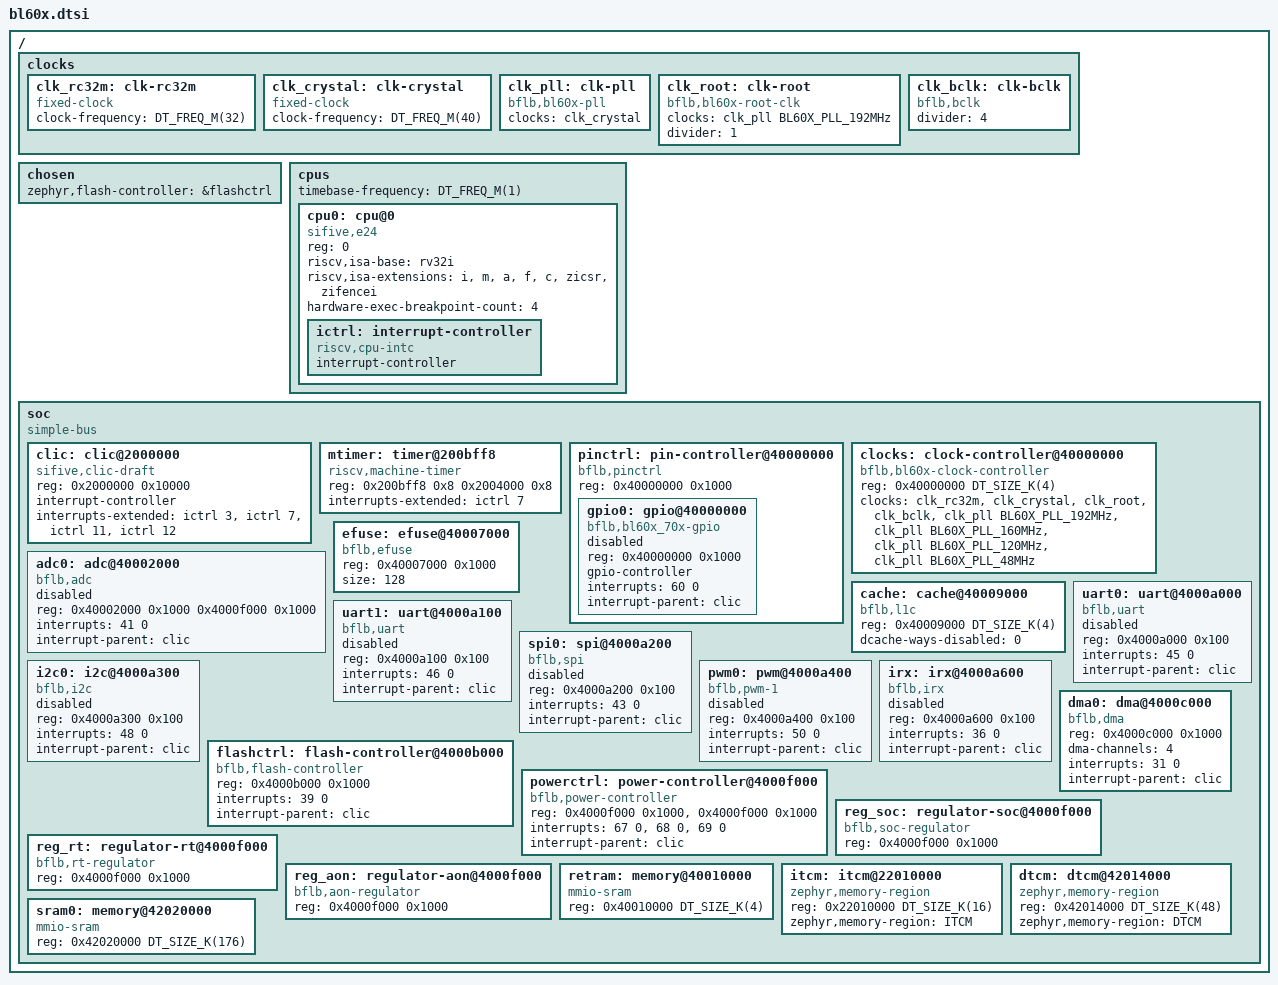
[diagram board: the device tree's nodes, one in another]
/*
 * Copyright (c) 2021-2025 ATL Electronics
 * Copyright (c) 2024-2026 MASSDRIVER EI (massdriver.space)
 *
 * SPDX-License-Identifier: Apache-2.0
 */

#include <freq.h>
#include <mem.h>
#include <zephyr/dt-bindings/pinctrl/bflb-common-pinctrl.h>
#include <zephyr/dt-bindings/pinctrl/bl60x-pinctrl.h>
#include <zephyr/dt-bindings/clock/bflb_bl60x_clock.h>
#include <zephyr/dt-bindings/gpio/gpio.h>
#include <zephyr/dt-bindings/input/input-event-codes.h>
#include <zephyr/dt-bindings/i2c/i2c.h>
#include <zephyr/dt-bindings/spi/spi.h>
#include <zephyr/dt-bindings/pwm/pwm.h>
#include <zephyr/dt-bindings/adc/adc.h>

/ {
	#address-cells = <1>;
	#size-cells = <1>;

	clocks {
		clk_rc32m: clk-rc32m {
			#clock-cells = <0>;
			compatible = "fixed-clock";
			clock-frequency = <DT_FREQ_M(32)>;
			status = "okay";
		};

		clk_crystal: clk-crystal {
			#clock-cells = <0>;
			compatible = "fixed-clock";
			clock-frequency = <DT_FREQ_M(40)>;
			status = "okay";
		};

		clk_pll: clk-pll {
			#clock-cells = <1>;
			compatible = "bflb,bl60x-pll";
			clocks = <&clk_crystal>;
			status = "okay";
		};

		clk_root: clk-root {
			#clock-cells = <0>;
			compatible = "bflb,bl60x-root-clk";
			clocks = <&clk_pll BL60X_PLL_192MHz>;
			divider = <1>;
			status = "okay";
		};

		clk_bclk: clk-bclk {
			#clock-cells = <0>;
			compatible = "bflb,bclk";
			divider = <4>;
			status = "okay";
		};
	};

	chosen {
		zephyr,flash-controller = &flashctrl;
	};

	cpus {
		#address-cells = <1>;
		#size-cells = <0>;
		timebase-frequency = <DT_FREQ_M(1)>;

		cpu0: cpu@0 {
			device_type = "cpu";
			compatible = "sifive,e24", "riscv";
			reg = <0>;
			riscv,isa-base = "rv32i";
			riscv,isa-extensions = "i", "m", "a", "f", "c", "zicsr", "zifencei";
			hardware-exec-breakpoint-count = <4>;
			status = "okay";

			ictrl: interrupt-controller {
				#address-cells = <0>;
				#interrupt-cells = <1>;
				compatible = "riscv,cpu-intc";
				interrupt-controller;
			};
		};
	};

	soc {
		compatible = "simple-bus";
		#address-cells = <1>;
		#size-cells = <1>;
		ranges;

		clic: clic@2000000 {
			compatible = "sifive,clic-draft";
			reg = <0x2000000 0x10000>;
			#address-cells = <0>;
			#interrupt-cells = <2>;

			interrupt-controller;
			interrupts-extended = <&ictrl 3 &ictrl 7 &ictrl 11 &ictrl 12>;
			interrupt-names = "msip", /* Machine Software Interrupt */
					  "mtip", /* Machine Timer interrupt    */
					  "meip", /* Machine External Interrupt */
					  "csip"; /* CLIC Software Interrupt    */
		};

		mtimer: timer@200bff8 {
			compatible = "riscv,machine-timer";
			reg = <0x200bff8 0x8 0x2004000 0x8>;
			reg-names = "mtime", "mtimecmp";

			interrupts-extended = <&ictrl 7>;
		};

		pinctrl: pin-controller@40000000 {
			compatible = "bflb,pinctrl";
			reg = <0x40000000 0x1000>;
			ranges = <0x40000000 0x40000000 0x1000>;
			#address-cells = <1>;
			#size-cells = <1>;
			status = "okay";

			gpio0: gpio@40000000 {
				compatible = "bflb,bl60x_70x-gpio";
				reg = <0x40000000 0x1000>;
				#gpio-cells = <2>;
				status = "disabled";

				gpio-controller;
				interrupts = <60 0>;
				interrupt-parent = <&clic>;
			};
		};

		clocks: clock-controller@40000000 {
			compatible = "bflb,bl60x-clock-controller", "bflb,clock-controller";
			reg = <0x40000000 DT_SIZE_K(4)>;
			#clock-cells = <1>;
			status = "okay";
			clocks = <&clk_rc32m>, <&clk_crystal>, <&clk_root>, <&clk_bclk>,
				 <&clk_pll BL60X_PLL_192MHz>, <&clk_pll BL60X_PLL_160MHz>,
				 <&clk_pll BL60X_PLL_120MHz>, <&clk_pll BL60X_PLL_48MHz>;
			clock-names = "rc32m", "crystal", "root", "bclk",
				      "pll_192", "pll_160",
				      "pll_120", "pll_48";
		};

		adc0: adc@40002000 {
			compatible = "bflb,adc";
			reg = <0x40002000 0x1000 0x4000f000 0x1000>;
			#io-channel-cells = <1>;
			#address-cells = <1>;
			#size-cells = <0>;
			status = "disabled";

			interrupts = <41 0>;
			interrupt-parent = <&clic>;
		};

		efuse: efuse@40007000 {
			compatible = "bflb,efuse";
			reg = <0x40007000 0x1000>;
			status = "okay";
			size = <128>;
		};

		cache: cache@40009000 {
			reg = <0x40009000 DT_SIZE_K(4)>;
			compatible = "bflb,l1c";
			dcache-ways-disabled = <0>;
		};

		uart0: uart@4000a000 {
			compatible = "bflb,uart";
			reg = <0x4000a000 0x100>;
			interrupts = <45 0>;
			interrupt-parent = <&clic>;
			status = "disabled";
		};

		uart1: uart@4000a100 {
			compatible = "bflb,uart";
			reg = <0x4000a100 0x100>;
			interrupts = <46 0>;
			interrupt-parent = <&clic>;
			status = "disabled";
		};

		spi0: spi@4000a200 {
			compatible = "bflb,spi";
			reg = <0x4000a200 0x100>;
			#address-cells = <1>;
			#size-cells = <0>;
			status = "disabled";

			interrupts = <43 0>;
			interrupt-parent = <&clic>;
		};

		i2c0: i2c@4000a300 {
			compatible = "bflb,i2c";
			reg = <0x4000a300 0x100>;
			#address-cells = <1>;
			#size-cells = <0>;
			status = "disabled";

			interrupts = <48 0>;
			interrupt-parent = <&clic>;
		};

		pwm0: pwm@4000a400 {
			compatible = "bflb,pwm-1";
			reg = <0x4000a400 0x100>;
			#pwm-cells = <3>;
			status = "disabled";

			interrupts = <50 0>;
			interrupt-parent = <&clic>;
		};

		irx: irx@4000a600 {
			compatible = "bflb,irx";
			reg = <0x4000a600 0x100>;
			#address-cells = <1>;
			#size-cells = <0>;
			status = "disabled";

			interrupts = <36 0>;
			interrupt-parent = <&clic>;
		};

		flashctrl: flash-controller@4000b000 {
			compatible = "bflb,flash-controller";
			reg = <0x4000b000 0x1000>;
			#address-cells = <1>;
			#size-cells = <1>;
			status = "okay";

			interrupts = <39 0>;
			interrupt-parent = <&clic>;
		};

		dma0: dma@4000c000 {
			compatible = "bflb,dma";
			reg = <0x4000c000 0x1000>;
			#dma-cells = <2>;
			dma-channels = <4>;

			interrupts = <31 0>;
			interrupt-parent = <&clic>;
		};

		powerctrl: power-controller@4000f000 {
			compatible = "bflb,power-controller";
			reg = <0x4000f000 0x1000>, <0x4000f000 0x1000>;
			reg-names = "hbn", "aon";
			status = "okay";

			interrupts = <67 0>, <68 0>, <69 0>;
			interrupt-parent = <&clic>;
			interrupt-names = "hbn0", "hbn1", "bor";
		};

		reg_soc: regulator-soc@4000f000 {
			compatible = "bflb,soc-regulator";
			reg = <0x4000f000 0x1000>;
			status = "okay";
		};

		reg_rt: regulator-rt@4000f000 {
			compatible = "bflb,rt-regulator";
			reg = <0x4000f000 0x1000>;
			status = "okay";
		};

		reg_aon: regulator-aon@4000f000 {
			compatible = "bflb,aon-regulator";
			reg = <0x4000f000 0x1000>;
			status = "okay";
		};

		retram: memory@40010000 {
			compatible = "mmio-sram";
			reg = <0x40010000 DT_SIZE_K(4)>;
		};

		itcm: itcm@22010000 {
			compatible = "zephyr,memory-region", "sifive,dtim0";
			reg = <0x22010000 DT_SIZE_K(16)>;
			zephyr,memory-region = "ITCM";
		};

		dtcm: dtcm@42014000 {
			compatible = "zephyr,memory-region", "sifive,dtim0";
			reg = <0x42014000 DT_SIZE_K(48)>;
			zephyr,memory-region = "DTCM";
		};

		sram0: memory@42020000 {
			compatible = "mmio-sram";
			reg = <0x42020000 DT_SIZE_K(176)>;
		};
	};
};
